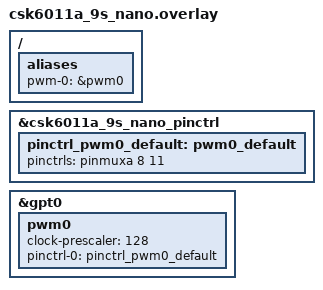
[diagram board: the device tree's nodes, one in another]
/ {
    aliases {
            pwm-0 = &pwm0;
    };
};

&csk6011a_9s_nano_pinctrl{
    /* PWM alternate function*/
    pinctrl_pwm0_default: pwm0_default{
        pinctrls = <&pinmuxa 8 11>;
    };
            
};

&gpt0 {
	status = "okay";

	pwm0: pwm0 {
                clock-prescaler = <128>;
                status = "okay";
	};

};

&pwm0 {
        pinctrl-0 = <&pinctrl_pwm0_default>; 
        pinctrl-names = "default";
        status = "okay";
};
